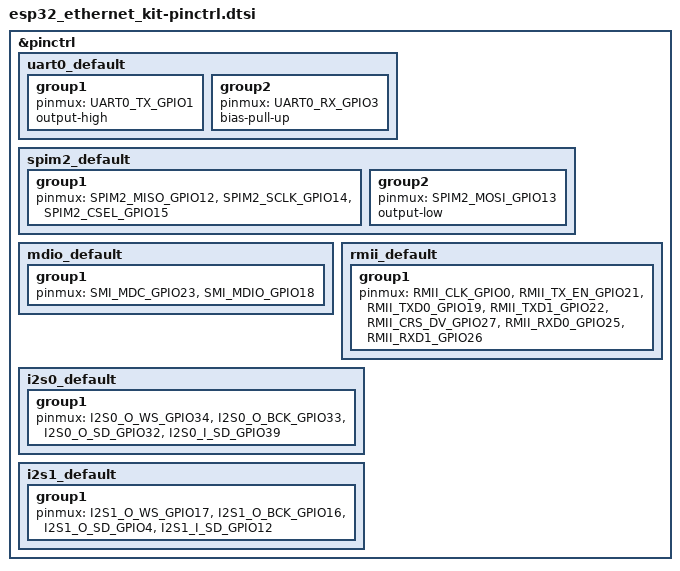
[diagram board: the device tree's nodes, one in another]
/*
 * Copyright (c) 2022-2025 Grant Ramsay <grant.ramsay@hotmail.com>
 *
 * SPDX-License-Identifier: Apache-2.0
 */

#include <zephyr/dt-bindings/pinctrl/esp32-pinctrl.h>

&pinctrl {
	uart0_default: uart0_default {
		group1 {
			pinmux = <UART0_TX_GPIO1>;
			output-high;
		};

		group2 {
			pinmux = <UART0_RX_GPIO3>;
			bias-pull-up;
		};
	};

	spim2_default: spim2_default {
		group1 {
			pinmux = <SPIM2_MISO_GPIO12>,
				 <SPIM2_SCLK_GPIO14>,
				 <SPIM2_CSEL_GPIO15>;
		};

		group2 {
			pinmux = <SPIM2_MOSI_GPIO13>;
			output-low;
		};
	};

	mdio_default: mdio_default {
		group1 {
			pinmux = <SMI_MDC_GPIO23>,
				 <SMI_MDIO_GPIO18>;
		};
	};

	rmii_default: rmii_default {
		group1 {
			pinmux = <RMII_CLK_GPIO0>,
				 <RMII_TX_EN_GPIO21>,
				 <RMII_TXD0_GPIO19>,
				 <RMII_TXD1_GPIO22>,
				 <RMII_CRS_DV_GPIO27>,
				 <RMII_RXD0_GPIO25>,
				 <RMII_RXD1_GPIO26>;
		};
	};

	i2s0_default: i2s0_default {
		group1 {
			pinmux = <I2S0_O_WS_GPIO34>,
				 <I2S0_O_BCK_GPIO33>,
				 <I2S0_O_SD_GPIO32>,
				 <I2S0_I_SD_GPIO39>;
		};
	};

	i2s1_default: i2s1_default {
		group1 {
			pinmux = <I2S1_O_WS_GPIO17>,
				 <I2S1_O_BCK_GPIO16>,
				 <I2S1_O_SD_GPIO4>,
				 <I2S1_I_SD_GPIO12>;
		};
	};
};
